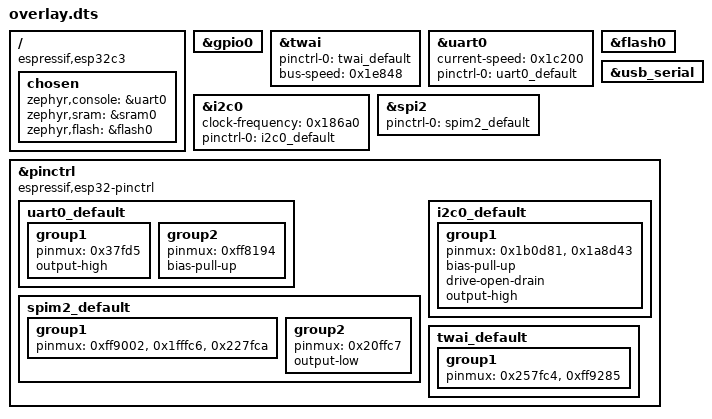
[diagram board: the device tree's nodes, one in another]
/ {
	compatible = "espressif,esp32c3";
	chosen {
		zephyr,console = &uart0;
		zephyr,sram = &sram0;
		zephyr,flash = &flash0;
	};
};
&gpio0{
	status = "okay";
};
&twai{
	pinctrl-0 = < &twai_default >;
	pinctrl-names = "default";
	bus-speed = < 0x1e848 >;
};
&uart0{
	status = "okay";
	current-speed = < 0x1c200 >;
	pinctrl-0 = < &uart0_default >;
	pinctrl-names = "default";
};
&i2c0{
	status = "okay";
	clock-frequency = < 0x186a0 >;
	pinctrl-0 = < &i2c0_default >;
	pinctrl-names = "default";
};
&spi2{
	status = "okay";
	#address-cells = < 0x1 >;
	#size-cells = < 0x0 >;
	pinctrl-0 = < &spim2_default >;
	pinctrl-names = "default";
};
&flash0{
	status = "okay";
};
&usb_serial{
	status = "okay";
};
&pinctrl{
	compatible = "espressif,esp32-pinctrl";
	status = "okay";
	uart0_default: uart0_default {
		group1 {
			pinmux = < 0x37fd5 >;
			output-high;
		};
		group2 {
			pinmux = < 0xff8194 >;
			bias-pull-up;
		};
	};
	spim2_default: spim2_default {
		group1 {
			pinmux = < 0xff9002 >, < 0x1fffc6 >, < 0x227fca >;
		};
		group2 {
			pinmux = < 0x20ffc7 >;
			output-low;
		};
	};
	i2c0_default: i2c0_default {
		group1 {
			pinmux = < 0x1b0d81 >, < 0x1a8d43 >;
			bias-pull-up;
			drive-open-drain;
			output-high;
		};
	};
	twai_default: twai_default {
		group1 {
			pinmux = < 0x257fc4 >, < 0xff9285 >;
		};
	};
};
